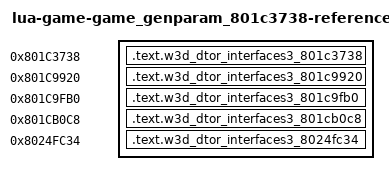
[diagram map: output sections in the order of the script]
/* Generated reference-only placements. All bodies are source-built. */
OUTPUT_FORMAT("elf32-powerpc")
OUTPUT_ARCH(powerpc)
ENTRY(w3d_dtor_interfaces3_801c3738)
_SDA_BASE_ = 0x804b2540;
_SDA2_BASE_ = 0x804c2540;
fn_801c9134 = 0x801c9134;
fn_801ea138 = 0x801ea138;
fn_801ea740 = 0x801ea740;
w3d_vtable_80414cb8 = 0x80414cb8;
w3d_vtable_80416258 = 0x80416258;
w3d_vtable_804162f8 = 0x804162f8;
w3d_vtable_80416348 = 0x80416348;
w3d_vtable_8041b6b8 = 0x8041b6b8;
SECTIONS {
  .text.w3d_dtor_interfaces3_801c3738 0x801c3738 : { *(.text.w3d_dtor_interfaces3_801c3738) }
  .text.w3d_dtor_interfaces3_801c9920 0x801c9920 : { *(.text.w3d_dtor_interfaces3_801c9920) }
  .text.w3d_dtor_interfaces3_801c9fb0 0x801c9fb0 : { *(.text.w3d_dtor_interfaces3_801c9fb0) }
  .text.w3d_dtor_interfaces3_801cb0c8 0x801cb0c8 : { *(.text.w3d_dtor_interfaces3_801cb0c8) }
  .text.w3d_dtor_interfaces3_8024fc34 0x8024fc34 : { *(.text.w3d_dtor_interfaces3_8024fc34) }
  /DISCARD/ : { *(.text*) *(.rodata*) *(.data*) *(.bss*) *(.sdata*) *(.sbss*) *(.comment) }
}
